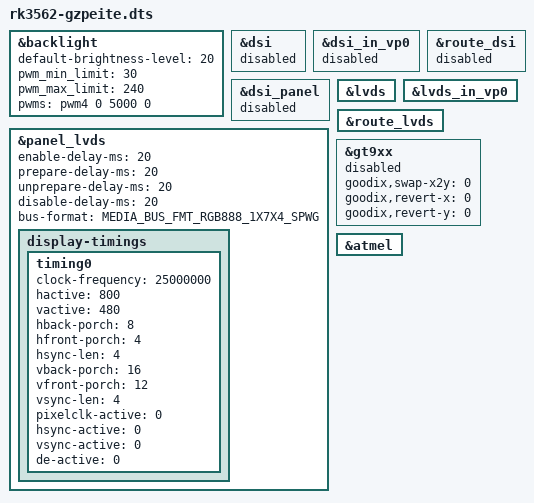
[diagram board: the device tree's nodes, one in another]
/dts-v1/;

#include "rk3562-gzpeite.dtsi"

&backlight {
  status = "okay";
  default-brightness-level = <20>;
  pwm_min_limit   = <30>;
  pwm_max_limit   = <240>;
//  pwms = <&pwm4 0 25000 0>;
  pwms = <&pwm4 0 5000 0>;
};

///////////////////////////////////////////////////////////////////////////////////////////////

&dsi {
  status = "disabled";
};

&dsi_in_vp0 {
  status = "disabled";
};

&route_dsi {
  status = "disabled";
};

&dsi_panel {
  status = "disabled";
};

///////////////////////////////////////////////////////////////////////////////////////////////

&lvds {
  status = "okay";
};

&lvds_in_vp0 {
  status = "okay";
};

&route_lvds {
  status = "okay";
};

&panel_lvds {
  status = "okay";
  enable-delay-ms = <20>;
  prepare-delay-ms = <20>;
  unprepare-delay-ms = <20>;
  disable-delay-ms = <20>;

  //  0x101B - MEDIA_BUS_FMT_RGB666_1X7X3_JEIDA jeida-18
  //  0x1012 - MEDIA_BUS_FMT_RGB888_1X7X4_JEIDA jeida-24
  //  0x1010 - MEDIA_BUS_FMT_RGB666_1X7X3_SPWG  vesa-18
  //  0x1011 - MEDIA_BUS_FMT_RGB888_1X7X4_SPWG  vesa-24

  //1024*600 signal channel LVDS
  bus-format = <MEDIA_BUS_FMT_RGB888_1X7X4_SPWG>;
//   display-timings {

//     timing0: timing0 {
//       clock-frequency = <55000000>;
//       hactive = <1024>;
//       vactive = <600>;
//       hback-porch = <190>;
//       hfront-porch = <130>;
//       hsync-len = <100>;
//       vback-porch = <23>;
//       vfront-porch = <12>;
//       vsync-len = <1>;
//       pixelclk-active = <0>;
//       hsync-active = <0>;
//       vsync-active = <0>;
//       de-active = <0>;
//     };
//   };
  //   display-timings {
  //   timing0: timing0 {
  //     clock-frequency = <23000000>;
  //     hactive = <800>;
  //     vactive = <480>;
  //     hback-porch = <4>;
  //     hfront-porch = <4>;
  //     hsync-len = <2>;
  //     vback-porch = <8>;
  //     vfront-porch = <8>;
  //     vsync-len = <2>;
  //     pixelclk-active = <0>;
  //     hsync-active = <0>;
  //     vsync-active = <0>;
  //     de-active = <0>;
  //   };
  // };
   display-timings {
    timing0: timing0 {
      clock-frequency = <25000000>;
      hactive = <800>;
      vactive = <480>;
      hback-porch = <8>;
      hfront-porch = <4>;
      hsync-len = <4>;
      vback-porch = <16>;
      vfront-porch = <12>;
      vsync-len = <4>;
      pixelclk-active = <0>;
      hsync-active = <0>;
      vsync-active = <0>;
      de-active = <0>;
    };
  };

  //   display-timings {
  //   timing0: timing0 {
  //     clock-frequency = <27000000>;
  //     hactive = <800>;
  //     vactive = <480>;
  //     hback-porch = <24>;
  //     hfront-porch = <24>;
  //     hsync-len = <8>;
  //     vback-porch = <24>;
  //     vfront-porch = <24>;
  //     vsync-len = <8>;
  //     pixelclk-active = <0>;
  //     hsync-active = <0>;
  //     vsync-active = <0>;
  //     de-active = <0>;
  //   };
  // };

  //   display-timings {
  //   timing0: timing0 {
  //     clock-frequency = <27000000>;
  //     hactive = <800>;
  //     vactive = <480>;
  //     hback-porch = <10>;
  //     hfront-porch = <80>;
  //     hsync-len = <5>;
  //     vback-porch = <20>;
  //     vfront-porch = <80>;
  //     vsync-len = <3>;
  //     pixelclk-active = <0>;
  //     hsync-active = <0>;
  //     vsync-active = <0>;
  //     de-active = <0>;
  //   };
  // };


  //    display-timings {
  //   timing0: timing0 {
  //     clock-frequency = <9000000>;
  //     hactive = <480>;
  //     vactive = <272>;
  //     hback-porch = <43>;//43
  //     hfront-porch = <2>;//8
  //     hsync-len = <4>;
  //     vback-porch = <12>;
  //     vfront-porch = <8>;
  //     vsync-len = <4>;
  //     pixelclk-active = <0>;
  //     hsync-active = <0>;
  //     vsync-active = <0>;
  //     de-active = <0>;
  //   };
  // };

  //   display-timings {
  //   timing0: timing0 {
  //     clock-frequency = <12000000>;
  //     hactive = <480>;
  //     vactive = <272>;
  //     hback-porch = <43>;
  //     hfront-porch = <75>;
  //     hsync-len = <43>;
  //     vback-porch = <12>;
  //     vfront-porch = <37>;
  //     vsync-len = <12>;
  //     pixelclk-active = <0>;
  //     hsync-active = <0>;
  //     vsync-active = <0>;
  //     de-active = <0>;
  //   };
  // };

};

///////////////////////////////////////////////////////////////////////////////////////////////

&gt9xx {
  status = "disabled";
  goodix,swap-x2y = <0>;
  goodix,revert-x = <0>;
  goodix,revert-y = <0>;
};

&atmel {
    status = "okay";
		
	};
